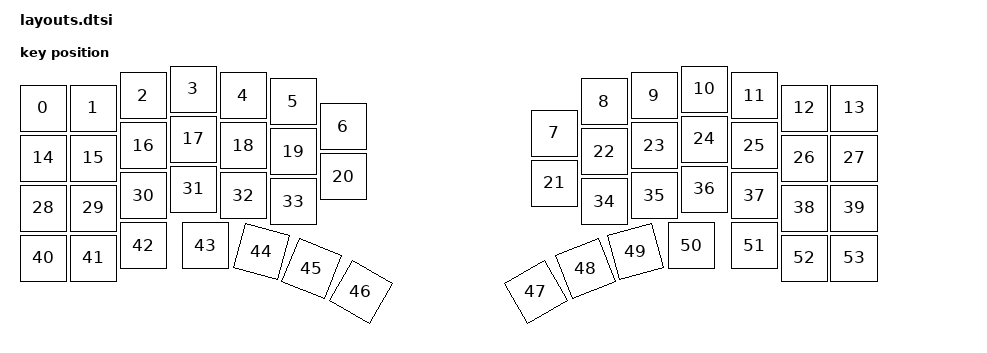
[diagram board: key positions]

#include <physical_layouts.dtsi>
/ {
    physical_layout0: physical_layout0 {
        compatible = "zmk,physical-layout";
        display-name = "Layout";
        keys
            = <&key_physical_attrs 100 100 50 63 0 0 0>
			,<&key_physical_attrs 100 100 150 63 0 0 0>
			,<&key_physical_attrs 100 100 250 38 0 0 0>
			,<&key_physical_attrs 100 100 350 25 0 0 0>
			,<&key_physical_attrs 100 100 450 38 0 0 0>
			,<&key_physical_attrs 100 100 550 50 0 0 0>
			,<&key_physical_attrs 100 100 650 100 0 0 0>
			,<&key_physical_attrs 100 100 1072 113 0 0 0>
			,<&key_physical_attrs 100 100 1172 50 0 0 0>
			,<&key_physical_attrs 100 100 1272 38 0 0 0>
			,<&key_physical_attrs 100 100 1372 25 0 0 0>
			,<&key_physical_attrs 100 100 1472 38 0 0 0>
			,<&key_physical_attrs 100 100 1572 63 0 0 0>
			,<&key_physical_attrs 100 100 1672 63 0 0 0>
			,<&key_physical_attrs 100 100 50 163 0 0 0>
			,<&key_physical_attrs 100 100 150 163 0 0 0>
			,<&key_physical_attrs 100 100 250 138 0 0 0>
			,<&key_physical_attrs 100 100 350 125 0 0 0>
			,<&key_physical_attrs 100 100 450 138 0 0 0>
			,<&key_physical_attrs 100 100 550 150 0 0 0>
			,<&key_physical_attrs 100 100 650 200 0 0 0>
			,<&key_physical_attrs 100 100 1072 213 0 0 0>
			,<&key_physical_attrs 100 100 1172 150 0 0 0>
			,<&key_physical_attrs 100 100 1272 138 0 0 0>
			,<&key_physical_attrs 100 100 1372 125 0 0 0>
			,<&key_physical_attrs 100 100 1472 138 0 0 0>
			,<&key_physical_attrs 100 100 1572 163 0 0 0>
			,<&key_physical_attrs 100 100 1672 163 0 0 0>
			,<&key_physical_attrs 100 100 50 263 0 0 0>
			,<&key_physical_attrs 100 100 150 263 0 0 0>
			,<&key_physical_attrs 100 100 250 238 0 0 0>
			,<&key_physical_attrs 100 100 350 225 0 0 0>
			,<&key_physical_attrs 100 100 450 238 0 0 0>
			,<&key_physical_attrs 100 100 550 250 0 0 0>
			,<&key_physical_attrs 100 100 1172 250 0 0 0>
			,<&key_physical_attrs 100 100 1272 238 0 0 0>
			,<&key_physical_attrs 100 100 1372 225 0 0 0>
			,<&key_physical_attrs 100 100 1472 238 0 0 0>
			,<&key_physical_attrs 100 100 1572 263 0 0 0>
			,<&key_physical_attrs 100 100 1672 263 0 0 0>
			,<&key_physical_attrs 100 100 50 363 0 0 0>
			,<&key_physical_attrs 100 100 150 363 0 0 0>
			,<&key_physical_attrs 100 100 250 338 0 0 0>
			,<&key_physical_attrs 100 100 375 338 0 0 0>
			,<&key_physical_attrs 100 100 502 339 1500 502 339>
			,<&key_physical_attrs 100 100 610 369 2200 610 369>
			,<&key_physical_attrs 100 100 717 413 3000 717 413>
			,<&key_physical_attrs 100 100 1017 463 (-3000) 1017 463>
			,<&key_physical_attrs 100 100 1120 406 (-2200) 1120 406>
			,<&key_physical_attrs 100 100 1224 365 (-1500) 1224 365>
			,<&key_physical_attrs 100 100 1347 338 0 0 0>
			,<&key_physical_attrs 100 100 1472 338 0 0 0>
			,<&key_physical_attrs 100 100 1572 363 0 0 0>
			,<&key_physical_attrs 100 100 1672 363 0 0 0>
            ;
    };

		trackball_listener: trackball_listener {
			compatible = "zmk,input-listener";
			status = "disabled";
		};
};
    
